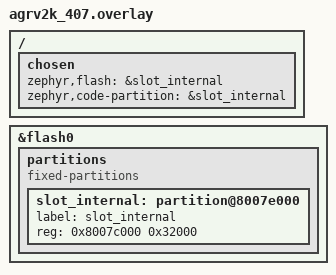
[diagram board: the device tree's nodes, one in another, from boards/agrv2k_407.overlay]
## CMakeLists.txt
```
# SPDX-License-Identifier: Apache-2.0

cmake_minimum_required(VERSION 3.20.0)
find_package(Zephyr REQUIRED HINTS $ENV{ZEPHYR_BASE})
project(spi_boot_app)

target_sources(app PRIVATE src/main.c)
```

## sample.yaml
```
# SPDX-License-Identifier: Apache-2.0
sample:
  name: spi_boot_app
  description: |
    Payload for samples/spi_boot_loader: linked XIP into the loader's on-die
    application slot (the legacy RAM-linked variant went away with `mode
    external`). Needs the loader's bitstream/board setup (canonical 200 MHz
    bitstream routes the on-board flash to SPI0), so the cases are build_only.
tests:
  sample.spi_boot_app.agm_agrv2k_407:
    build_only: true
    platform_allow:
      - agrv2k_407
    integration_platforms:
      - agrv2k_407
    tags:
      - ci_build
      - hal_ag32
  # The same payload as the *signed* flow needs it (CONFIG_BOOT_AGM_SIG_*):
  # linked one MCUboot header past the slot base, because the loader hands a
  # container's payload to `slot + hdr_size` and the header occupies that gap
  # (imgtool's --pin-header; sign_image.py fills the same gap). The dev board proved
  # the flow with an ad-hoc -D first (peripherals 3.26.32) -- this is the
  # regression net for the layout, and the only scenario whose address differs.
  sample.spi_boot_app.internal_signed.agm_agrv2k_407:
    build_only: true
    extra_configs:
      - CONFIG_ROM_START_OFFSET=0x20
    platform_allow:
      - agrv2k_407
    integration_platforms:
      - agrv2k_407
    tags:
      - ci_build
      - hal_ag32
```

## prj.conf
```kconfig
# SPDX-License-Identifier: Apache-2.0
#
# XIP into the application slot (0x8007c000 with the default layout, see
# boards/agrv2k_407.overlay). spi_boot_loader writes this image into the slot
# and jumps to it -- the only place a payload runs, now that the legacy
# `mode external` (copy into SRAM) path is gone.
CONFIG_XIP=y

# Link into /chosen/zephyr,code-partition (the slot set by
# boards/agrv2k_407.overlay). Zephyr defaults this off, and with it
# off the code-partition has no effect: the image is linked at the flash base
# regardless (measured -- the first attempt produced entry 0x80000000).
CONFIG_USE_DT_CODE_PARTITION=y

# Chain-loaded image: the loader already brought the fabric up and switched
# the CPU onto the bitstream's PLL. Repeating soc.c's bring-up would
# deactivate the fabric this image is clocked from (see prj.conf and
# the port record (peripherals) 3.26.9).
CONFIG_AGM_SOC_SKIP_CLOCK_INIT=y

CONFIG_SERIAL=y
CONFIG_UART_CONSOLE=y
CONFIG_PRINTK=y
CONFIG_STDOUT_CONSOLE=y

CONFIG_MAIN_STACK_SIZE=2048
```

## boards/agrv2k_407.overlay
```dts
/* SPDX-License-Identifier: Apache-2.0 */
/*
 * The payload is linked XIP into the application slot that
 * samples/spi_boot_loader owns -- that is the only place it runs, now that the
 * legacy `mode external` (copy to SRAM) path is gone.
 * With the default layout that slot is 0x8007c000 + 200 KiB (see
 * boards/agrv2k_407.overlay there: loader 96 KiB, record, two 200 KiB sides,
 * then the slot; the fabric reservation starts at 0x800e7000).
 *
 * Build it with:
 *   west build -d /tmp/b_boot_app_slot -b agrv2k_407 --pristine=auto \
 *       modules/hal_ag32/samples/spi_boot_app
 * (the signed flow adds -DCONFIG_ROM_START_OFFSET=0x20, see sample.yaml)
 */
&flash0 {
	partitions {
		compatible = "fixed-partitions";
		#address-cells = <1>;
		#size-cells = <1>;

		slot_internal: partition@8007e000 {
			label = "slot_internal";
			reg = <0x8007c000 0x32000>;
		};
	};
};

/ {
	chosen {
		/* Pointing zephyr,flash at the slot (instead of the whole
		 * flash0) is what actually moves the link address on this
		 * architecture: the RISC-V linker takes the ROM origin from
		 * that chosen node's base, and CONFIG_FLASH_LOAD_OFFSET is 0
		 * here (Zephyr's USE_DT_CODE_PARTITION/load-offset machinery
		 * only shifts ARM-style linkers -- measured 2026-09-17: with
		 * only code-partition set, the image still linked at
		 * 0x80000000). */
		zephyr,flash = &slot_internal;
		zephyr,code-partition = &slot_internal;
	};
};
```

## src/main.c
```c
/*
 * SPDX-License-Identifier: Apache-2.0
 *
 * Payload for samples/spi_boot_loader.
 *
 * This image is built to run from SRAM (CONFIG_XIP=n, see prj.conf and
 * boards/agrv2k_407.overlay): the loader reads it out of the on-board SPI
 * NOR, copies it to its link address and jumps into it. The banner below is
 * what tells us on the console that the jump worked -- the loader prints
 * its own banner first.
 *
 * It also answers the loader's trial-boot handshake: the banner is this
 * image's self-test, so right after it the image says "this one works" with
 * agm_boot_trial_confirm(). That is what turns the trial slot into a
 * confirmed one on the next boot, and it is what stops the watchdog the
 * loader armed -- an image that never calls it (or hangs before it) gets
 * reset and, after three attempts, rolled back (see
 * CONFIG_BOOT_AGM_TRIAL_WATCHDOG).
 */

#include <zephyr/kernel.h>
#include <zephyr/drivers/misc/boot_agm.h>
#include <zephyr/sys/printk.h>

int main(void)
{
	uint32_t tick = 0;
	int ret;

	printk("\n");
	printk("=========================================\n");
	printk(" spi_boot_app: running\n");
	printk(" main    : %p\n", (void *)main);
	printk(" This line only appears if spi_boot_loader\n");
	printk(" loaded this image -- from the external SPI NOR\n");
	printk(" into RAM, or into the on-die slot.\n");
	printk("=========================================\n");

	/* Self-test passed: answer the handshake. */
	ret = agm_boot_trial_confirm();
	if (ret == 0) {
		printk(" confirmed: this slot becomes permanent on the next boot\n");
	} else if (ret == -ENOENT) {
		printk(" not a trial boot - nothing to confirm\n");
	} else {
		printk(" confirm failed (%d) - the loader will roll back after "
		       "its attempts run out\n", ret);
	}

	while (1) {
		printk("[ram-app %u] uptime=%u ms\n", tick++,
		       (uint32_t)k_uptime_get());
		k_msleep(1000);
	}

	return 0;
}
```
